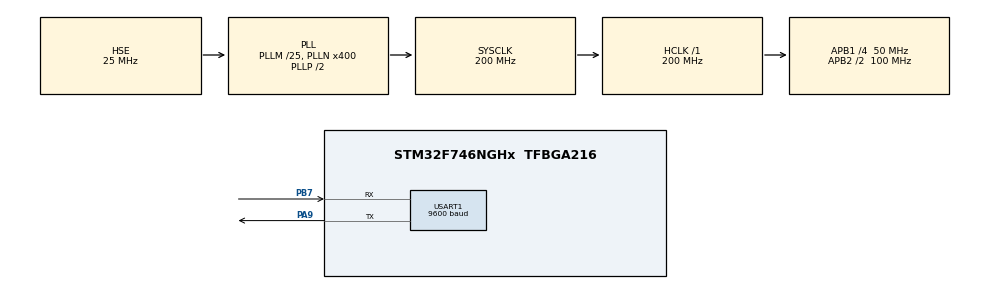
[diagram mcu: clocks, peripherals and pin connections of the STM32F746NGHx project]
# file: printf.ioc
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Mcu.Family=STM32F7
Mcu.Name=STM32F746NGHx
Mcu.Package=TFBGA216
NVIC.PriorityGroup=NVIC_PRIORITYGROUP_4
PA9.Mode=Asynchronous
PA9.Signal=USART1_TX
PB7.Mode=Asynchronous
PB7.Signal=USART1_RX
PH0/OSC_IN.Mode=HSE-External-Oscillator
PH0/OSC_IN.Signal=RCC_OSC_IN
PH1/OSC_OUT.Mode=HSE-External-Oscillator
PH1/OSC_OUT.Signal=RCC_OSC_OUT
ProjectManager.HeapSize=0x200
ProjectManager.StackSize=0x400
ProjectManager.TargetToolchain=MDK-ARM V5
RCC.AHBFreq_Value=200000000
RCC.APB1CLKDivider=RCC_HCLK_DIV4
RCC.APB1Freq_Value=50000000
RCC.APB1TimFreq_Value=100000000
RCC.APB2CLKDivider=RCC_HCLK_DIV2
RCC.APB2Freq_Value=100000000
RCC.APB2TimFreq_Value=200000000
RCC.CortexFreq_Value=200000000
RCC.HCLKFreq_Value=200000000
RCC.HSE_VALUE=25000000
RCC.HSI_VALUE=16000000
RCC.LSE_VALUE=32768
RCC.PLL48CLockSelection=RCC_CLK48SOURCE_PLLSAIP
RCC.PLLI2SN=100
RCC.PLLM=25
RCC.PLLN=400
RCC.PLLQ=9
RCC.PLLSAIN=384
RCC.PLLSAIP=RCC_PLLSAIP_DIV8
RCC.PLLSAIR=5
RCC.PLLSAIRDiv=RCC_PLLSAIDIVR_8
RCC.PLLSourceVirtual=RCC_PLLSOURCE_HSE
RCC.SDMMCClockSelection=RCC_SDMMC1CLKSOURCE_CLK48
RCC.SYSCLKFreq_VALUE=200000000
RCC.SYSCLKSource=RCC_SYSCLKSOURCE_PLLCLK
RCC.USBFreq_Value=48000000
RCC.VCOOutputFreq_Value=400000000
USART1.BaudRate=9600
USART1.VirtualMode-Asynchronous=VM_ASYNC
USART1.WordLength=WORDLENGTH_8B
board=32F746GDISCOVERY

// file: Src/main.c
/**
  ******************************************************************************
  * @file           : main.c
  * @brief          : Main program body
  ******************************************************************************
  ** This notice applies to any and all portions of this file
  * that are not between comment pairs USER CODE BEGIN and
  * USER CODE END. Other portions of this file, whether
  * inserted by the user or by software development tools
  * are owned by their respective copyright owners.
  *
  * COPYRIGHT(c) 2018 STMicroelectronics
  *
  * Redistribution and use in source and binary forms, with or without modification,
  * are permitted provided that the following conditions are met:
  *   1. Redistributions of source code must retain the above copyright notice,
  *      this list of conditions and the following disclaimer.
  *   2. Redistributions in binary form must reproduce the above copyright notice,
  *      this list of conditions and the following disclaimer in the documentation
  *      and/or other materials provided with the distribution.
  *   3. Neither the name of STMicroelectronics nor the names of its contributors
  *      may be used to endorse or promote products derived from this software
  *      without specific prior written permission.
  *
  * THIS SOFTWARE IS PROVIDED BY THE COPYRIGHT HOLDERS AND CONTRIBUTORS "AS IS"
  * AND ANY EXPRESS OR IMPLIED WARRANTIES, INCLUDING, BUT NOT LIMITED TO, THE
  * IMPLIED WARRANTIES OF MERCHANTABILITY AND FITNESS FOR A PARTICULAR PURPOSE ARE
  * DISCLAIMED. IN NO EVENT SHALL THE COPYRIGHT HOLDER OR CONTRIBUTORS BE LIABLE
  * FOR ANY DIRECT, INDIRECT, INCIDENTAL, SPECIAL, EXEMPLARY, OR CONSEQUENTIAL
  * DAMAGES (INCLUDING, BUT NOT LIMITED TO, PROCUREMENT OF SUBSTITUTE GOODS OR
  * SERVICES; LOSS OF USE, DATA, OR PROFITS; OR BUSINESS INTERRUPTION) HOWEVER
  * CAUSED AND ON ANY THEORY OF LIABILITY, WHETHER IN CONTRACT, STRICT LIABILITY,
  * OR TORT (INCLUDING NEGLIGENCE OR OTHERWISE) ARISING IN ANY WAY OUT OF THE USE
  * OF THIS SOFTWARE, EVEN IF ADVISED OF THE POSSIBILITY OF SUCH DAMAGE.
  *
  ******************************************************************************
  */
#include "main.h"
#include "stm32f7xx_hal.h"

/* USER CODE BEGIN Includes */

#ifdef __GNUC__					//This is added from the KGP Talkie
	#define PUTCHAR_PROTOTYPE int __io_putchar(int ch)
#else
	#define PUTCHAR_PROTOTYPE int fputc(int ch,FILE *f)
#endif	/*	__GNUC__    */

/* USER CODE END Includes */

UART_HandleTypeDef huart1;

/* USER CODE BEGIN PV */
/* Private variables ---------------------------------------------------------*/

	int c = 0;
/* USER CODE END PV */

void SystemClock_Config(void);
static void MX_GPIO_Init(void);
static void MX_USART1_UART_Init(void);

/* USER CODE BEGIN PFP */
/* Private function prototypes -----------------------------------------------*/

char ch[100] = "HELLO FROM ARM";
/* USER CODE END PFP */

/* USER CODE BEGIN 0 */

PUTCHAR_PROTOTYPE
{
	HAL_UART_Transmit(&huart1,(uint8_t *)&ch,1,0xFFFF);
	return ch;
}

/* USER CODE END 0 */

int main(void)
{

  /* MCU Configuration----------------------------------------------------------*/

  /* Reset of all peripherals, Initializes the Flash interface and the Systick. */
  HAL_Init();

  /* Configure the system clock */
  SystemClock_Config();

  /* Initialize all configured peripherals */
  MX_GPIO_Init();
  MX_USART1_UART_Init();
  /* USER CODE BEGIN 2 */

printf("STM32F7 Calibration Completed!\r\n");
	HAL_Delay(500);

  /* USER CODE END 2 */

  /* Infinite loop */
  /* USER CODE BEGIN WHILE */
  while (1)
  {
		HAL_UART_Transmit(&huart1,(uint8_t *)&ch,100,0xFFFF);
		printf("\t");
		printf("The value of counter is %d",c);
		printf("\r\n");
		c++;
		HAL_Delay(500);

  /* USER CODE END WHILE */

  }

}

void SystemClock_Config(void)
{

  RCC_OscInitTypeDef RCC_OscInitStruct;
  RCC_ClkInitTypeDef RCC_ClkInitStruct;
  RCC_PeriphCLKInitTypeDef PeriphClkInitStruct;

    /**Configure the main internal regulator output voltage
    */
  __HAL_RCC_PWR_CLK_ENABLE();

  __HAL_PWR_VOLTAGESCALING_CONFIG(PWR_REGULATOR_VOLTAGE_SCALE1);

    /**Initializes the CPU, AHB and APB busses clocks
    */
  RCC_OscInitStruct.OscillatorType = RCC_OSCILLATORTYPE_HSE;
  RCC_OscInitStruct.HSEState = RCC_HSE_ON;
  RCC_OscInitStruct.PLL.PLLState = RCC_PLL_ON;
  RCC_OscInitStruct.PLL.PLLSource = RCC_PLLSOURCE_HSE;
  RCC_OscInitStruct.PLL.PLLM = 25;
  RCC_OscInitStruct.PLL.PLLN = 400;
  RCC_OscInitStruct.PLL.PLLP = RCC_PLLP_DIV2;
  RCC_OscInitStruct.PLL.PLLQ = 9;
  if (HAL_RCC_OscConfig(&RCC_OscInitStruct) != HAL_OK)
  {
    _Error_Handler(__FILE__, __LINE__);
  }

    /**Activate the Over-Drive mode
    */
  if (HAL_PWREx_EnableOverDrive() != HAL_OK)
  {
    _Error_Handler(__FILE__, __LINE__);
  }

    /**Initializes the CPU, AHB and APB busses clocks
    */
  RCC_ClkInitStruct.ClockType = RCC_CLOCKTYPE_HCLK|RCC_CLOCKTYPE_SYSCLK
                              |RCC_CLOCKTYPE_PCLK1|RCC_CLOCKTYPE_PCLK2;
  RCC_ClkInitStruct.SYSCLKSource = RCC_SYSCLKSOURCE_PLLCLK;
  RCC_ClkInitStruct.AHBCLKDivider = RCC_SYSCLK_DIV1;
  RCC_ClkInitStruct.APB1CLKDivider = RCC_HCLK_DIV4;
  RCC_ClkInitStruct.APB2CLKDivider = RCC_HCLK_DIV2;

  if (HAL_RCC_ClockConfig(&RCC_ClkInitStruct, FLASH_LATENCY_6) != HAL_OK)
  {
    _Error_Handler(__FILE__, __LINE__);
  }

  PeriphClkInitStruct.PeriphClockSelection = RCC_PERIPHCLK_USART1;
  PeriphClkInitStruct.Usart1ClockSelection = RCC_USART1CLKSOURCE_PCLK2;
  if (HAL_RCCEx_PeriphCLKConfig(&PeriphClkInitStruct) != HAL_OK)
  {
    _Error_Handler(__FILE__, __LINE__);
  }

    /**Configure the Systick interrupt time
    */
  HAL_SYSTICK_Config(HAL_RCC_GetHCLKFreq()/1000);

    /**Configure the Systick
    */
  HAL_SYSTICK_CLKSourceConfig(SYSTICK_CLKSOURCE_HCLK);

  /* SysTick_IRQn interrupt configuration */
  HAL_NVIC_SetPriority(SysTick_IRQn, 0, 0);
}

/* USART1 init function */
static void MX_USART1_UART_Init(void)
{

  huart1.Instance = USART1;
  huart1.Init.BaudRate = 9600;
  huart1.Init.WordLength = UART_WORDLENGTH_8B;
  huart1.Init.StopBits = UART_STOPBITS_1;
  huart1.Init.Parity = UART_PARITY_NONE;
  huart1.Init.Mode = UART_MODE_TX_RX;
  huart1.Init.HwFlowCtl = UART_HWCONTROL_NONE;
  huart1.Init.OverSampling = UART_OVERSAMPLING_16;
  huart1.Init.OneBitSampling = UART_ONE_BIT_SAMPLE_DISABLE;
  huart1.AdvancedInit.AdvFeatureInit = UART_ADVFEATURE_NO_INIT;
  if (HAL_UART_Init(&huart1) != HAL_OK)
  {
    _Error_Handler(__FILE__, __LINE__);
  }

}

/** Configure pins as
        * Analog
        * Input
        * Output
        * EVENT_OUT
        * EXTI
*/
static void MX_GPIO_Init(void)
{

  /* GPIO Ports Clock Enable */
  __HAL_RCC_GPIOB_CLK_ENABLE();
  __HAL_RCC_GPIOA_CLK_ENABLE();
  __HAL_RCC_GPIOH_CLK_ENABLE();

}

void _Error_Handler(char *file, int line)
{
  while(1)
  {
  }
}

/************************ (C) COPYRIGHT STMicroelectronics *****END OF FILE****/
